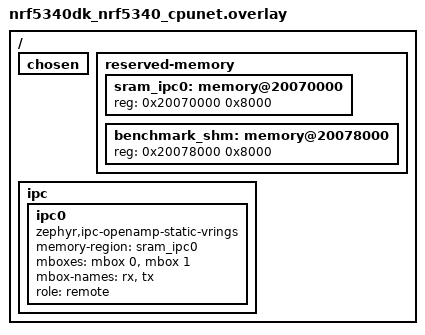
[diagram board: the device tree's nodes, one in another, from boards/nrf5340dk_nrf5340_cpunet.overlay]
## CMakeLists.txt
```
# SPDX-License-Identifier: Apache-2.0

cmake_minimum_required(VERSION 3.20.0)

find_package(Zephyr REQUIRED HINTS $ENV{ZEPHYR_BASE})
project(ble-framework-attacks-cpunet)

FILE(GLOB app_sources src/*.c)
target_sources(app PRIVATE ${app_sources})

zephyr_include_directories(
        ${CMAKE_CURRENT_SOURCE_DIR}/include
)

zephyr_include_directories(
        ${CMAKE_CURRENT_SOURCE_DIR}/../common_nRF5340/include
)
```

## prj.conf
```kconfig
CONFIG_IPC_SERVICE=y
CONFIG_MBOX=y

CONFIG_HEAP_MEM_POOL_SIZE=4096

CONFIG_MAIN_STACK_SIZE=2048
CONFIG_SYSTEM_WORKQUEUE_STACK_SIZE=2048

CONFIG_BT=y
CONFIG_BT_HCI_RAW=y
CONFIG_BT_MAX_CONN=5

# Enable and adjust the below value as necessary to match Controller values
# CONFIG_BT_BUF_EVT_RX_COUNT=16
# CONFIG_BT_BUF_EVT_RX_SIZE=255
# CONFIG_BT_BUF_ACL_RX_SIZE=255
# CONFIG_BT_BUF_ACL_TX_SIZE=251
# CONFIG_BT_BUF_CMD_TX_SIZE=255

# for debug purpose only
CONFIG_LOG=y

CONFIG_USE_SEGGER_RTT=y
CONFIG_LOG_BACKEND_RTT=y
CONFIG_LOG_BACKEND_UART=n

CONFIG_BT_LOG_LEVEL_DBG=y

# DLE
CONFIG_BT_DATA_LEN_UPDATE=y
CONFIG_BT_BUF_ACL_TX_SIZE=251
CONFIG_BT_BUF_ACL_RX_SIZE=251
CONFIG_BT_CTLR_DATA_LENGTH_MAX=251

# stop the scan to repeatedly showing the same devices/AD packets
CONFIG_BT_CTLR_DUP_FILTER_LEN=128

# if one board lost/deleted the LTK, pairing is started from scratch instead of throwing a pairing failure
CONFIG_BT_SMP_ALLOW_UNAUTH_OVERWRITE=y
```

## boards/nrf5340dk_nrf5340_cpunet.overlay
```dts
/delete-node/ &sram0_shared;

/ {
	chosen {
		/delete-property/ zephyr,ipc_shm;
	};

	reserved-memory {
		#address-cells = <1>;
		#size-cells = <1>;
		ranges;

		sram_ipc0: memory@20070000 {
			reg = <0x20070000 0x8000>;
		};

		benchmark_shm: memory@20078000 {
			reg = <0x20078000 0x8000>;
		};
	};

	ipc {
		/delete-node/ ipc0;

		ipc0: ipc0 {
			compatible = "zephyr,ipc-openamp-static-vrings";
			memory-region = <&sram_ipc0>;

			mboxes = <&mbox 0>, <&mbox 1>;
			mbox-names = "rx", "tx";

			role = "remote";
			status = "okay";
		};
	};
};
```

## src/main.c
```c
/*
 * Copyright (c) 2019-2021 Nordic Semiconductor ASA
 *
 * SPDX-License-Identifier: Apache-2.0
 */

#include <errno.h>
#include <stddef.h>
#include <stdio.h>
#include <string.h>

#include <zephyr/device.h>
#include <zephyr/kernel.h>
#include <zephyr/sys/byteorder.h>
#include <zephyr/sys/util.h>

#include <zephyr/ipc/ipc_service.h>

#include <zephyr/net_buf.h>
#include <zephyr/bluetooth/bluetooth.h>
#include <zephyr/bluetooth/l2cap.h>
#include <zephyr/bluetooth/hci.h>
#include <zephyr/bluetooth/buf.h>
#include <zephyr/bluetooth/hci_raw.h>
#include <zephyr/bluetooth/hci_vs.h>

#include <zephyr/logging/log_ctrl.h>
#include <zephyr/logging/log.h>
#include "../include/ipc_service.h"
#include "../../common_nRF5340/include/ipc_service.h"
#include <hal/nrf_timer.h>


LOG_MODULE_REGISTER(hci_ipc, CONFIG_BT_LOG_LEVEL);

BUILD_ASSERT(!IS_ENABLED(CONFIG_BT_CONN) || IS_ENABLED(CONFIG_BT_HCI_ACL_FLOW_CONTROL),
	     "HCI IPC driver can drop ACL data without Controller-to-Host ACL flow control");

static struct ipc_ept hci_ept;
static struct ipc_ept benchmark_ept;

static K_THREAD_STACK_DEFINE(tx_thread_stack, CONFIG_BT_HCI_TX_STACK_SIZE);
static struct k_thread tx_thread_data;
static K_FIFO_DEFINE(tx_queue);
static K_SEM_DEFINE(ipc_bound_sem, 0, 1);
#if defined(CONFIG_BT_CTLR_ASSERT_HANDLER) || defined(CONFIG_BT_HCI_VS_FATAL_ERROR)
/* A flag used to store information if the IPC endpoint has already been bound. The end point can't
 * be used before that happens.
 */
static bool ipc_ept_ready;
#endif /* CONFIG_BT_CTLR_ASSERT_HANDLER || CONFIG_BT_HCI_VS_FATAL_ERROR */

#define HCI_IPC_CMD 0x01
#define HCI_IPC_ACL 0x02
#define HCI_IPC_SCO 0x03
#define HCI_IPC_EVT 0x04
#define HCI_IPC_ISO 0x05

#define HCI_FATAL_ERR_MSG true
#define HCI_REGULAR_MSG false

static struct net_buf *hci_ipc_cmd_recv(uint8_t *data, size_t remaining)
{
	struct bt_hci_cmd_hdr *hdr = (void *)data;
	struct net_buf *buf;

	if (remaining < sizeof(*hdr)) {
		LOG_ERR("Not enough data for command header");
		return NULL;
	}

	buf = bt_buf_get_tx(BT_BUF_CMD, K_NO_WAIT, hdr, sizeof(*hdr));
	if (buf) {
		data += sizeof(*hdr);
		remaining -= sizeof(*hdr);
	} else {
		LOG_ERR("No available command buffers!");
		return NULL;
	}

	if (remaining != hdr->param_len) {
		LOG_ERR("Command payload length is not correct");
		net_buf_unref(buf);
		return NULL;
	}

	if (remaining > net_buf_tailroom(buf)) {
		LOG_ERR("Not enough space in buffer");
		net_buf_unref(buf);
		return NULL;
	}

	LOG_DBG("len %u", hdr->param_len);
	net_buf_add_mem(buf, data, remaining);

	return buf;
}

static struct net_buf *hci_ipc_acl_recv(uint8_t *data, size_t remaining)
{
	struct bt_hci_acl_hdr *hdr = (void *)data;
	struct net_buf *buf;

	if (remaining < sizeof(*hdr)) {
		LOG_ERR("Not enough data for ACL header");
		return NULL;
	}

	buf = bt_buf_get_tx(BT_BUF_ACL_OUT, K_NO_WAIT, hdr, sizeof(*hdr));
	if (buf) {
		data += sizeof(*hdr);
		remaining -= sizeof(*hdr);
	} else {
		LOG_ERR("No available ACL buffers!");
		return NULL;
	}

	if (remaining != sys_le16_to_cpu(hdr->len)) {
		LOG_ERR("ACL payload length is not correct");
		net_buf_unref(buf);
		return NULL;
	}

	if (remaining > net_buf_tailroom(buf)) {
		LOG_ERR("Not enough space in buffer");
		net_buf_unref(buf);
		return NULL;
	}

	LOG_DBG("len %u", remaining);
	net_buf_add_mem(buf, data, remaining);

	return buf;
}

static struct net_buf *hci_ipc_iso_recv(uint8_t *data, size_t remaining)
{
	struct bt_hci_iso_hdr *hdr = (void *)data;
	struct net_buf *buf;

	if (remaining < sizeof(*hdr)) {
		LOG_ERR("Not enough data for ISO header");
		return NULL;
	}

	buf = bt_buf_get_tx(BT_BUF_ISO_OUT, K_NO_WAIT, hdr, sizeof(*hdr));
	if (buf) {
		data += sizeof(*hdr);
		remaining -= sizeof(*hdr);
	} else {
		LOG_ERR("No available ISO buffers!");
		return NULL;
	}

	if (remaining != bt_iso_hdr_len(sys_le16_to_cpu(hdr->len))) {
		LOG_ERR("ISO payload length is not correct");
		net_buf_unref(buf);
		return NULL;
	}

	if (remaining > net_buf_tailroom(buf)) {
		LOG_ERR("Not enough space in buffer");
		net_buf_unref(buf);
		return NULL;
	}

	LOG_DBG("len %zu", remaining);
	net_buf_add_mem(buf, data, remaining);

	return buf;
}

static void hci_ipc_rx(uint8_t *data, size_t len)
{
	uint8_t pkt_indicator;
	struct net_buf *buf = NULL;
	size_t remaining = len;

	LOG_HEXDUMP_DBG(data, len, "IPC data:");

	pkt_indicator = *data++;
	remaining -= sizeof(pkt_indicator);

	switch (pkt_indicator) {
	case HCI_IPC_CMD:
		buf = hci_ipc_cmd_recv(data, remaining);
		break;

	case HCI_IPC_ACL:
		buf = hci_ipc_acl_recv(data, remaining);
		break;

	case HCI_IPC_ISO:
		buf = hci_ipc_iso_recv(data, remaining);
		break;

	default:
		LOG_ERR("Unknown HCI type %u", pkt_indicator);
		return;
	}

	if (buf) {
		LOG_INF("Putting HCI command into tx_queue");
		k_fifo_put(&tx_queue, buf);
		LOG_INF("HCI command queued");
		LOG_HEXDUMP_DBG(buf->data, buf->len, "Final net buffer:");
	}
}

static void tx_thread(void *p1, void *p2, void *p3)
{
	LOG_INF("TX THREAD STARTED");

	while (1) {
		struct net_buf *buf;
		int err;

		/* Wait until a buffer is available */
		buf = k_fifo_get(&tx_queue, K_FOREVER);
		/* Pass buffer to the stack */
		LOG_DBG("CPUNET: sending to controller\n");
		err = bt_send(buf);
		LOG_DBG("CPUNET: bt_send returned %d\n", err);
		if (err) {
			LOG_ERR("Unable to send (err %d)", err);
			net_buf_unref(buf);
		}

		/* Give other threads a chance to run if tx_queue keeps getting
		 * new data all the time.
		 */
		k_yield();
	}
}

static void hci_ipc_send(struct net_buf *buf, bool is_fatal_err)
{
	uint8_t retries = 0;
	int ret;

	LOG_DBG("buf %p type %u len %u", buf, buf->data[0], buf->len);

	LOG_HEXDUMP_DBG(buf->data, buf->len, "Final HCI buffer:");

	do {
		ret = ipc_service_send(&hci_ept, buf->data, buf->len);
		if (ret < 0) {
			retries++;
			if (retries > 10) {
				/* Default backend (rpmsg_virtio) has a timeout of 150ms. */
				LOG_WRN("IPC send has been blocked for 1.5 seconds.");
				retries = 0;
			}

			/* The function can be called by the application main thread,
			 * bt_ctlr_assert_handle and k_sys_fatal_error_handler. In case of a call by
			 * Bluetooth Controller assert handler or system fatal error handler the
			 * call can be from ISR context, hence there is no thread to yield. Besides
			 * that both handlers implement a policy to provide error information and
			 * stop the system in an infinite loop. The goal is to prevent any other
			 * damage to the system if one of such exeptional situations occur, hence
			 * call to k_yield is against it.
			 */
			if (is_fatal_err) {
				LOG_ERR("ipc_service_send error: %d", ret);
			} else {
				/* In the POSIX ARCH, code takes zero simulated time to execute,
				 * so busy wait loops become infinite loops, unless we
				 * force the loop to take a bit of time.
				 *
				 * This delay allows the IPC consumer to execute, thus making
				 * it possible to send more data over IPC afterwards.
				 */
				Z_SPIN_DELAY(500);
				k_yield();
			}
		}
	} while (ret < 0);

	LOG_INF("ipc_service_send sent %d/%u bytes", ret, buf->len);
	__ASSERT_NO_MSG(ret == buf->len);

	net_buf_unref(buf);
}

#if defined(CONFIG_BT_CTLR_ASSERT_HANDLER)
void bt_ctlr_assert_handle(char *file, uint32_t line)
{
	/* Disable interrupts, this is unrecoverable */
	(void)irq_lock();

#if defined(CONFIG_BT_HCI_VS_FATAL_ERROR)
	/* Generate an error event only when IPC service endpoint is already bound. */
	if (ipc_ept_ready) {
		/* Prepare vendor specific HCI debug event */
		struct net_buf *buf;

		buf = hci_vs_err_assert(file, line);
		if (buf != NULL) {
			/* Send the event over ipc */
			hci_ipc_send(buf, HCI_FATAL_ERR_MSG);
		} else {
			LOG_ERR("Can't create Fatal Error HCI event: %s at %d", __FILE__, __LINE__);
		}
	} else {
		LOG_ERR("IPC endpoint is not ready yet: %s at %d", __FILE__, __LINE__);
	}

	LOG_ERR("Halting system");

#else /* !CONFIG_BT_HCI_VS_FATAL_ERROR */
	LOG_ERR("Controller assert in: %s at %d", file, line);

#endif /* !CONFIG_BT_HCI_VS_FATAL_ERROR */

	/* Flush the logs before locking the CPU */
	LOG_PANIC();

	while (true) {
		k_cpu_idle();
	};

	CODE_UNREACHABLE;
}
#endif /* CONFIG_BT_CTLR_ASSERT_HANDLER */

#if defined(CONFIG_BT_HCI_VS_FATAL_ERROR)
void k_sys_fatal_error_handler(unsigned int reason, const struct arch_esf *esf)
{
	/* Disable interrupts, this is unrecoverable */
	(void)irq_lock();

	/* Generate an error event only when there is a stack frame and IPC service endpoint is
	 * already bound.
	 */
	if (esf != NULL && ipc_ept_ready) {
		/* Prepare vendor specific HCI debug event */
		struct net_buf *buf;

		buf = hci_vs_err_stack_frame(reason, esf);
		if (buf != NULL) {
			hci_ipc_send(buf, HCI_FATAL_ERR_MSG);
		} else {
			LOG_ERR("Can't create Fatal Error HCI event.\n");
		}
	}

	LOG_ERR("Halting system");

	/* Flush the logs before locking the CPU */
	LOG_PANIC();

	while (true) {
		k_cpu_idle();
	};

	CODE_UNREACHABLE;
}
#endif /* CONFIG_BT_HCI_VS_FATAL_ERROR */

static void hci_ept_bound(void *priv)
{
	k_sem_give(&ipc_bound_sem);
#if defined(CONFIG_BT_CTLR_ASSERT_HANDLER) || defined(CONFIG_BT_HCI_VS_FATAL_ERROR)
	ipc_ept_ready = true;
#endif /* CONFIG_BT_CTLR_ASSERT_HANDLER || CONFIG_BT_HCI_VS_FATAL_ERROR */
}

static void hci_ept_recv(const void *data, size_t len, void *priv)
{
	LOG_DBG("CPUNET: HCI RX %u bytes\n", len);
	LOG_INF("Received message of %u bytes.", len);
	hci_ipc_rx((uint8_t *) data, len);
}


static struct ipc_ept_cfg hci_ept_cfg = {
	.name = "nrf_bt_hci",
	.cb = {
		.bound    = hci_ept_bound,
		.received = hci_ept_recv,
	},
};

void init_timer(){
	NRF_TIMER2->TASKS_STOP = 1;
	NRF_TIMER2->MODE = TIMER_MODE_MODE_Timer;
	NRF_TIMER2->BITMODE = TIMER_BITMODE_BITMODE_32Bit;
	NRF_TIMER2->PRESCALER = 0;   // 1 / 16 MHz = 62.5 ns per Tick

	NRF_TIMER2->TASKS_CLEAR = 1;
	NRF_TIMER2->TASKS_START = 1;
}


static void benchmark_ept_bound(void *priv)
{
	// Optional: Flag oder Logausgabe setzen.
}

static void benchmark_ept_recv(const void *data, size_t len, void *priv)
{
	benchmark_command_received(data, len, priv);
}

static struct ipc_ept_cfg benchmark_ept_cfg = {
	.name = BENCHMARK_ENDPOINT_NAME,
	.cb = {
		.bound = benchmark_ept_bound,
		.received = benchmark_ept_recv,
	},
};



int main(void)
{
	LOG_INF("CPUNET MAIN START\n");

	int err;
	const struct device *hci_ipc_instance =
		DEVICE_DT_GET(DT_CHOSEN(zephyr_bt_hci_ipc));

	/* incoming events and data from the controller */
	static K_FIFO_DEFINE(rx_queue);

	LOG_DBG("Start");

	/* Enable the raw interface, this will in turn open the HCI driver */
	int ret = bt_enable_raw(&rx_queue);
	LOG_DBG("CPUNET: bt_enable_raw = %d\n", ret);

	/* Spawn the TX thread and start feeding commands and data to the
	 * controller
	 */
	k_thread_create(&tx_thread_data, tx_thread_stack,
			K_THREAD_STACK_SIZEOF(tx_thread_stack), tx_thread,
			NULL, NULL, NULL, K_PRIO_COOP(7), 0, K_NO_WAIT);
	k_thread_name_set(&tx_thread_data, "HCI ipc TX");

	/* Initialize IPC service instance and register endpoint. */
	err = ipc_service_open_instance(hci_ipc_instance);
	if (err < 0 && err != -EALREADY) {
		LOG_ERR("IPC service instance initialization failed: %d\n", err);
	}

	err = ipc_service_register_endpoint(hci_ipc_instance, &hci_ept, &hci_ept_cfg);
	if (err) {
		LOG_ERR("Registering endpoint failed with %d", err);
        return err;
	}

	err = ipc_service_register_endpoint(hci_ipc_instance, &benchmark_ept, &benchmark_ept_cfg);

	if (err) {
		LOG_ERR("Registering benchmark endpoint failed: %d", err);
        return err;
	}

	init_timer();

	k_sem_take(&ipc_bound_sem, K_FOREVER);
	LOG_DBG("CPUNET: HCI endpoint bound\n");

	while (1) {
		struct net_buf *buf;

		buf = k_fifo_get(&rx_queue, K_FOREVER);
		LOG_DBG("CPUNET: controller response, %u bytes\n", buf->len);
		hci_ipc_send(buf, HCI_REGULAR_MSG);
	}
	return 0;
}
```

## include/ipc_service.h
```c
void benchmark_command_received(const void *data, size_t len, void *priv);
```

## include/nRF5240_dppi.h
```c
#pragma once

#include <stdbool.h>
#include <stdint.h>

#if defined(CONFIG_SOC_COMPATIBLE_NRF5340_CPUNET)
#include <nrf5340_network.h>

#define ENCRYPT_START_DPPI_CHANNEL 0
#define DECRYPT_START_DPPI_CHANNEL 1
#define ENDCRYPT_END_DPPI_CHANNEL 2

void hal_radio_ccm_nRF5340_dppi_config();
void hal_radio_ccm_nRF5340_ppi_disable();
#endif
```

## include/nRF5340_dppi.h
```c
#pragma once

#include <stdbool.h>
#include <stdint.h>

#if defined(CONFIG_SOC_COMPATIBLE_NRF5340_CPUNET)
#include <nrf5340_network.h>

/*
* Everything related to KSGEN ENC start -> 0
* Everything related to KSGEN DECR start -> 1
* Everything related to KSGEN end -> 2
* Everything related to ENCR start -> 3
* Everything related to DECR start -> 4
* Everything related to ENDCRYPT -> 5
*/

/*
 * For benchmarking the nRF5340
 * Timer offsets /variables for capturing start and end of KSGEN and de-/encryption
 */

/* KSGEN */
#define HAL_EVENT_TIMER_KSGEN_START_ENC_CC_OFFSET 0
#define HAL_EVENT_TIMER_KSGEN_START_DECR_CC_OFFSET 1
/* Timer for the end of KSGEN*/
#define HAL_EVENT_TIMER_KSGEN_END_CC_OFFSET 2

/*
 * Different timer for encryption and decryption start, but the end event is the same, so we only need one timer for the end event.
 */
#define HAL_EVENT_TIMER_CCM_START_ENC_CC_OFFSET 3
#define HAL_EVENT_TIMER_CCM_START_DECR_CC_OFFSET 4
#define HAL_EVENT_TIMER_CCM_END_ENDCRYPT_CC_OFFSET 5

/* DPPI Channels */
#define KSGEN_END_DPPI_CHANNEL 2
#define ENDCRYPT_END_DPPI_CHANNEL 1 // this channel is exceptionally set to 1, because 5 is already in use

void hal_radio_ccm_nRF5340_dppi_config();
void hal_radio_ccm_nRF5340_ppi_disable();
#endif
```

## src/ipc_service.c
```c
#include <zephyr/ipc/ipc_service.h>
#include "../../common_nRF5340/include/ipc_service.h"
#include "../include/nRF5340_dppi.h"

void benchmark_command_received(
    const void *data,
    size_t len,
    void *priv
)
{
    if (len != sizeof(uint8_t)) {
        return;
    }

    uint8_t command = *(const uint8_t *)data;

    __DMB();

    switch (command) {
        case BENCHMARK_CMD_DPPI_CONFIG:
            hal_radio_ccm_nRF5340_dppi_config();
        break;

        case BENCHMARK_CMD_DPPI_DISABLE:
            hal_radio_ccm_nRF5340_ppi_disable();
        break;

        default:
            break;
    }
}
```

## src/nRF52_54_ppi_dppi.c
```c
#if defined(CONFIG_SOC_COMPATIBLE_NRF5340_CPUNET)
#include <hal/nrf_radio.h>
#include <hal/nrf_timer.h>
#include <hal/nrf_dppi.h>
#include <hal/nrf_ccm.h>
#include <nRF5340_dppi.h>
// load cmake with set(ENV{BOARD} nrf5340dk/nrf5340/cpunet) so that the following two functions does not throw any errors

void hal_radio_ccm_nRF5340_dppi_config() {

    /* ENCRYPTION */

    /* CCM EVENT_ENDKSGEN -> publish on DPPI channel ENCRYPT_START_DPPI_CHANNEL */
    nrf_ccm_publish_set(
        NRF_CCM,
        NRF_CCM_EVENT_ENDKSGEN,
        ENCRYPT_START_DPPI_CHANNEL
    );

    /* TIMER1 CAPTURE[0] subscribes to DPPI channel ENCRYPT_START_DPPI_CHANNEL */
    nrf_timer_subscribe_set(
        NRF_TIMER1,
        NRF_TIMER_TASK_CAPTURE0,
        ENCRYPT_START_DPPI_CHANNEL
    );

    /* Enable DPPI channel ENCRYPT_START_DPPI_CHANNEL in DPPIC */
    nrf_dppi_channels_enable(
        NRF_DPPIC,
        BIT(ENCRYPT_START_DPPI_CHANNEL)
    );


    /* DECRYPTION */
    /* RADIO EVENTS_PAYLOAD -> publish on DPPI channel DECRYPT_START_DPPI_CHANNEL */
    nrf_radio_publish_set(
        NRF_RADIO,
        NRF_RADIO_EVENT_ADDRESS,
        DECRYPT_START_DPPI_CHANNEL
    );

    /* TIMER1 CAPTURE[1] subscribes to DPPI channel DECRYPT_START_DPPI_CHANNEL */
    nrf_timer_subscribe_set(
        NRF_TIMER1,
        NRF_TIMER_TASK_CAPTURE1,
        DECRYPT_START_DPPI_CHANNEL
    );

    /* Enable DPPI channel DECRYPT_START_DPPI_CHANNEL in DPPIC */
    nrf_dppi_channels_enable(
        NRF_DPPIC,
        BIT(DECRYPT_START_DPPI_CHANNEL)
    );


    /* ENDCRYPTION */

    /* NRF_CCM EVENTS_ENDCRYPT -> publish on DPPI channel ENDCRYPT_END_DPPI_CHANNEL */
    nrf_ccm_publish_set(
        NRF_CCM,
        NRF_CCM_EVENT_END,
        ENDCRYPT_END_DPPI_CHANNEL
    );

    /* TIMER1 CAPTURE[2] subscribes to DPPI channel ENDCRYPT_END_DPPI_CHANNEL */
    nrf_timer_subscribe_set(
        NRF_TIMER1,
        NRF_TIMER_TASK_CAPTURE2,
        ENDCRYPT_END_DPPI_CHANNEL
    );

    /* Enable DPPI channel ENDCRYPT_END_DPPI_CHANNEL in DPPIC */
    nrf_dppi_channels_enable(
        NRF_DPPIC,
        BIT(ENDCRYPT_END_DPPI_CHANNEL)
    );
}

void hal_radio_ccm_nRF5340_ppi_disable() {
    /* ENCRYPTION */

    /* Disable DPPI channel ENCRYPT_START_DPPI_CHANNEL in DPPIC */
    nrf_dppi_channels_disable(
        NRF_DPPIC,
        BIT(ENCRYPT_START_DPPI_CHANNEL)
    );


    /* DECRYPTION */

    /* Disable DPPI channel DECRYPT_START_DPPI_CHANNEL in DPPIC */
    nrf_dppi_channels_disable(
        NRF_DPPIC,
        BIT(DECRYPT_START_DPPI_CHANNEL)
    );


    /* ENDCRYPTION */

    /* Disable DPPI channel ENDCRYPT_END_DPPI_CHANNEL in DPPIC */
    nrf_dppi_channels_disable(
        NRF_DPPIC,
        BIT(ENDCRYPT_END_DPPI_CHANNEL)
    );
}
#endif
```

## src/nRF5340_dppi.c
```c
#if defined(CONFIG_SOC_COMPATIBLE_NRF5340_CPUNET)
#include <hal/nrf_radio.h>
#include <hal/nrf_timer.h>
#include <hal/nrf_dppi.h>
#include <hal/nrf_ccm.h>
#include "../include/nRF5340_dppi.h"
// load cmake with set(ENV{BOARD} nrf5340dk/nrf5340/cpunet) so that the following two functions does not throw any errors

/*
* Everything related to KSGEN ENC start -> 0
* Everything related to KSGEN DECR start -> 1
* Everything related to KSGEN end -> 2
* Everything related to ENCR start -> 3
* Everything related to DECR start -> 4
* Everything related to ENDCRYPT -> 5
*/

void hal_radio_ccm_nRF5340_dppi_config() {

     /*
     * KSGEN
     */

    /*
     * ENCRYPTION:
     * start of KSGEN is triggered in SW -> radio.c, line 2532
     * in the function static void *radio_ccm_ext_tx_pkt_set(struct ccm *cnf, uint8_t pdu_type, void *pkt)
     * We do register this event/this task in a register of the TIMER3 instance.
     * We don't have a PPI channel for that anymore
     */

    /*
     * DECRYPTION:
     * start of KSGEN is triggered in SW -> radio.c, line 2342
     * static void *radio_ccm_ext_rx_pkt_set(struct ccm *cnf, uint8_t phy, uint8_t pdu_type, void *pkt)
     * We do register this event/this task in a register of the TIMER3 instance.
     * We don't have a PPI channel for that anymore
     */

    // ENDCR: when KSGEN ends

    /* CCM EVENT_ENDKSGEN -> publish on DPPI channel KSGEN_END_DPPI_CHANNEL */
    nrf_ccm_publish_set(
        NRF_CCM,
        NRF_CCM_EVENT_ENDKSGEN,
        KSGEN_END_DPPI_CHANNEL
    );

    /* TIMER1 CAPTURE[2] subscribes to DPPI channel ENCRYPT_START_DPPI_CHANNEL */
    nrf_timer_subscribe_set(
        NRF_TIMER2,
        NRF_TIMER_TASK_CAPTURE2,
        KSGEN_END_DPPI_CHANNEL
    );

    /* Enable DPPI channel ENCRYPT_START_DPPI_CHANNEL in DPPIC */
    nrf_dppi_channels_enable(
        NRF_DPPIC,
        BIT(KSGEN_END_DPPI_CHANNEL)
    );



    /* ENCRYPTION */

    /* CCM EVENT_ENDKSGEN -> publish on DPPI channel ENCRYPT_START_DPPI_CHANNEL */
    //nrf_ccm_publish_set(
    //    NRF_CCM,
    //    NRF_CCM_EVENT_ENDKSGEN,
    //    ENCRYPT_START_DPPI_CHANNEL
    //);

    /* KSGEN END und ENCRYPTION START are the same points in time. Therefore, TIMER1 CAPTURE[2] (KSGEN END)
     * and TIMER1 CAPTURE[3] (ENCRYPT start) subscribe to the same DPPI channel KSGEN_END_DPPI_CHANNEL */
    nrf_timer_subscribe_set(
        NRF_TIMER2,
        NRF_TIMER_TASK_CAPTURE3,
        KSGEN_END_DPPI_CHANNEL
    );

    /* Enable DPPI channel ENCRYPT_START_DPPI_CHANNEL in DPPIC */
    //nrf_dppi_channels_enable(
    //    NRF_DPPIC,
    //    BIT(ENCRYPT_START_DPPI_CHANNEL)
    //);


    /* DECRYPTION */
    /* RADIO EVENTS_ADDRESS -> publish on DPPI channel DECRYPT_START_DPPI_CHANNEL */
    //nrf_radio_publish_set(
    //    NRF_RADIO,
    //    NRF_RADIO_EVENT_ADDRESS,
    //    DECRYPT_START_DPPI_CHANNEL
    //);

    /* TIMER1 CAPTURE[4] subscribes to DPPI channel DECRYPT_START_DPPI_CHANNEL */
    //nrf_timer_subscribe_set(
    //    NRF_TIMER2,
    //    NRF_TIMER_TASK_CAPTURE4,
    //    DECRYPT_START_DPPI_CHANNEL
    //);

    /* Enable DPPI channel DECRYPT_START_DPPI_CHANNEL in DPPIC */
    //nrf_dppi_channels_enable(
    //    NRF_DPPIC,
    //    BIT(DECRYPT_START_DPPI_CHANNEL)
    //);

    nrf_timer_subscribe_set(
        NRF_TIMER2,
        NRF_TIMER_TASK_CAPTURE4,
        HAL_TRIGGER_CRYPT_PPI
    );


    /* ENDCRYPTION */

    /* NRF_CCM EVENTS_ENDCRYPT -> publish on DPPI channel ENDCRYPT_END_DPPI_CHANNEL */
    nrf_ccm_publish_set(
        NRF_CCM,
        NRF_CCM_EVENT_END,
        ENDCRYPT_END_DPPI_CHANNEL
    );

    /* TIMER1 CAPTURE[5] subscribes to DPPI channel ENDCRYPT_END_DPPI_CHANNEL */
    nrf_timer_subscribe_set(
        NRF_TIMER2,
        NRF_TIMER_TASK_CAPTURE5,
        ENDCRYPT_END_DPPI_CHANNEL
    );

    /* Enable DPPI channel ENDCRYPT_END_DPPI_CHANNEL in DPPIC */
    nrf_dppi_channels_enable(
        NRF_DPPIC,
        BIT(ENDCRYPT_END_DPPI_CHANNEL)
    );
}

void hal_radio_ccm_nRF5340_ppi_disable() {
    /* ENCRYPTION */

    /* Disable DPPI channel ENCRYPT_START_DPPI_CHANNEL in DPPIC */
    //nrf_dppi_channels_disable(
    //    NRF_DPPIC,
    //    BIT(ENCRYPT_START_DPPI_CHANNEL)
    //);


    /* KSGEN */

    /* Disable DPPI channel KSGEN_END_DPPI_CHANNEL in DPPIC */
    nrf_dppi_channels_disable(
        NRF_DPPIC,
        BIT(KSGEN_END_DPPI_CHANNEL)
    );

    /* ENDCRYPTION */

    /* Disable DPPI channel ENDCRYPT_END_DPPI_CHANNEL in DPPIC */
    nrf_dppi_channels_disable(
        NRF_DPPIC,
        BIT(ENDCRYPT_END_DPPI_CHANNEL)
    );
}
#endif
```
